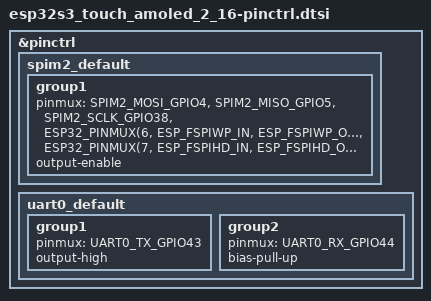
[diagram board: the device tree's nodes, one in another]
/* SPDX-License-Identifier: Apache-2.0 */
#include <dt-bindings/pinctrl/esp32s3-pinctrl.h>
#include <zephyr/dt-bindings/pinctrl/esp-pinctrl-common.h>
#include <zephyr/dt-bindings/pinctrl/esp32s3-gpio-sigmap.h>

&pinctrl {
    spim2_default: spim2_default {
        group1 {
            pinmux = <SPIM2_MOSI_GPIO4>, <SPIM2_MISO_GPIO5>,
                     <SPIM2_SCLK_GPIO38>,
                     <ESP32_PINMUX(6, ESP_FSPIWP_IN, ESP_FSPIWP_OUT)>,
                     <ESP32_PINMUX(7, ESP_FSPIHD_IN, ESP_FSPIHD_OUT)>;
            output-enable;
        };
    };
    uart0_default: uart0_default {
        group1 { pinmux = <UART0_TX_GPIO43>; output-high; };
        group2 { pinmux = <UART0_RX_GPIO44>; bias-pull-up; };
    };
};
